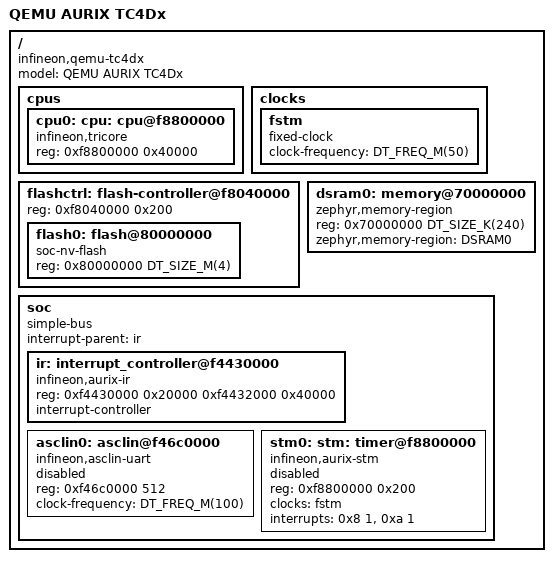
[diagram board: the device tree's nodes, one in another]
/*
 * SPDX-FileCopyrightText: Copyright (c) 2026 Infineon Technologies AG,
 * SPDX-FileCopyrightText: or an affiliate of Infineon Technologies AG. All rights reserved.
 * SPDX-FileCopyrightText: Copyright (c) 2026 Linumiz
 *
 * SPDX-License-Identifier: Apache-2.0
 */

#include <mem.h>
#include <freq.h>
#include <skeleton.dtsi>

/ {
	model = "QEMU AURIX TC4Dx";
	compatible = "infineon,qemu-tc4dx";

	cpus {
		#address-cells = <1>;
		#size-cells = <0>;

		cpu0: cpu: cpu@f8800000 {
			compatible = "infineon,tricore", "infineon,tc18";
			reg = <0xf8800000 0x40000>;
		};
	};

	clocks {
		fstm: fstm {
			compatible = "fixed-clock";
			clock-frequency = <DT_FREQ_M(50)>;
			#clock-cells = <0>;
		};
	};

	flashctrl: flash-controller@f8040000 {
		reg = <0xf8040000 0x200>;
		ranges;
		#address-cells = <1>;
		#size-cells = <1>;

		flash0: flash@80000000 {
			compatible = "soc-nv-flash";
			reg = <0x80000000 DT_SIZE_M(4)>;
			ranges = <0x0 0x80000000 DT_SIZE_M(4)>;
			#address-cells = <1>;
			#size-cells = <1>;
		};
	};

	dsram0: memory@70000000 {
		compatible = "zephyr,memory-region", "mmio-sram";
		reg = <0x70000000 DT_SIZE_K(240)>;
		zephyr,memory-region = "DSRAM0";
	};

	soc {
		#address-cells = <1>;
		#size-cells = <1>;
		interrupt-parent = <&ir>;
		compatible = "simple-bus";
		ranges;

		ir: interrupt_controller@f4430000 {
			compatible = "infineon,aurix-ir";
			reg = <0xf4430000 0x20000 0xf4432000 0x40000>;
			#address-cells = <0>;
			#interrupt-cells = <2>;
			interrupt-controller;
		};

		asclin0: asclin@f46c0000 {
			compatible = "infineon,asclin-uart";
			reg = <0xf46c0000 512>;
			clock-frequency = <DT_FREQ_M(100)>;
			status = "disabled";
		};

		stm0: stm: timer@f8800000 {
			compatible = "infineon,aurix-stm";
			reg = <0xf8800000 0x200>;
			clocks = <&fstm>;
			interrupts = <0x8 1>, <0xa 1>;
			status = "disabled";
		};
	};
};
